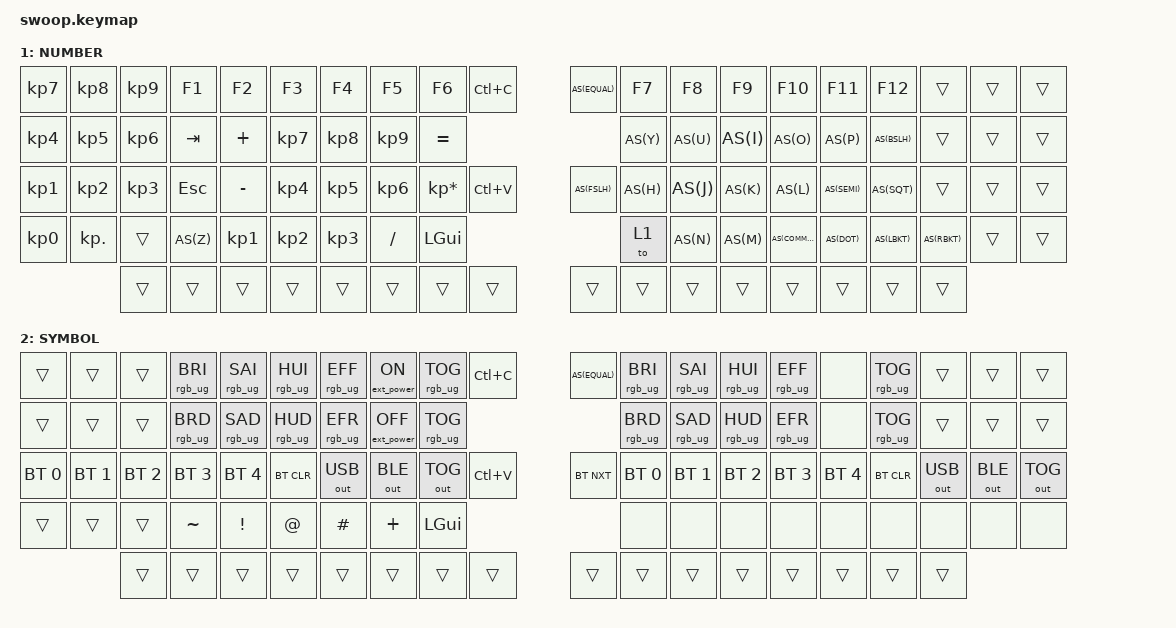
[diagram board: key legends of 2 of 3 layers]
#include <behaviors.dtsi>
#include <dt-bindings/zmk/keys.h>
#include <dt-bindings/zmk/rgb.h>
#include <dt-bindings/zmk/bt.h>
#include <dt-bindings/zmk/outputs.h>
#include <dt-bindings/zmk/ext_power.h>

#define DEFAULT 0
#define NUMBER  1
#define SYMBOL  2

#define AS(keycode) &as LS(keycode) keycode

/ {

       behaviors {
       as: auto_shift {
        compatible = "zmk,behavior-hold-tap";
        label = "AUTO_SHIFT";
        #binding-cells = <2>;
        tapping-term-ms = <160>;
        quick-tap-ms = <0>;
        flavor = "tap-preferred";
        bindings = <&kp>, <&kp>;
                };
modcp: mod_copy {
        compatible = "zmk,behavior-mod-morph";
        label = "MOD_COPY";
        #binding-cells = <0>;
        bindings = <&as LS(C) C>, <&kp C>;
        mods = <(MOD_LGUI | MOD_RGUI)>;
              };

        };


    macros {
        macro_phone: macro_phone {
            // 1351
            label = "MACRO_PHONE";
            compatible = "zmk,behavior-macro";
            #binding-cells = <0>;
            bindings
                = < &kp N1 &kp N3 &kp N5  &kp N1>
                ;
        };
        macro_email_q: macro_email_q {
            // 2894512440@qq.com
            label = "MACRO_EMAIL_QQ";
            compatible = "zmk,behavior-macro";
            #binding-cells = <0>;
            bindings 
                = < &kp N2 &kp N8 &kp N9 &kp N4 &kp N5 &kp  N1 &kp N2 &kp N4 &kp N4 &kp N0 
                    &kp AT &kp Q &kp Q &kp DOT  &kp C &kp O &kp M>
                ;
        };
        macro_email_g: macro_email_g {
            // 135115
            compatible = "zmk,behavior-macro";
            label = "MACRO_EMAIL_GMAIL";
            #binding-cells = <0>;
            bindings
                = < &kp N1 &kp N3 &kp N5  &kp N1 &kp N1 &kp N5 >
                ;
        };

    };


    keymap {
       compatible = "zmk,keymap";
        default_layer {
            label = "DEFAULT";
            bindings = <
  &kp KP_N7 &kp KP_N8 &kp KP_N9 &kp ESC &kp N1 &kp N2 &kp N3 &kp N4  &kp N5 &kp DEL       AS(EQUAL)AS(N6) AS(N7) AS(N8)  AS(N9) AS(N0) &kp MINUS &kp F10  &kp F11   &kp F12 
   &kp KP_N4 &kp KP_N5 &kp KP_N6 &kp TAB  &kp Q &kp W &kp E &kp R &kp T                                          AS(Y) AS(U) AS(I) AS(O) AS(P) AS(BSLH) &kp F7 &kp F8  &kp F9
   &kp KP_N1 &kp KP_N2 &kp KP_N3 &kp LSHFT  &kp A &kp S &kp D &kp F &kp G &kp ENTER                           AS(FSLH) AS(H)  AS(J) AS(K) AS(L) AS(SEMI) AS(SQT) &kp F4 &kp F5 &kp F6
   &kp KP_N0 &kp BSPC &kp LCTRL &kp Z &kp X &kp C &kp V &kp B &kp LALT                         &to 1 AS(N) AS(M) AS(COMMA) AS(DOT) AS(LBKT) AS(RBKT)  &kp F1 &kp F2 
    &kp DOWN &kp LGUI &kp LEFT &kp UP &kp RIGHT &kp SPACE &kp SPACE &kp SPACE                     &kp DEL &lt 2 LEFT &lt 1 RIGHT &kp C_VOL_UP  &kp C_VOL_DN  &kp C_BRI_UP
 
            >;
        };
            number_layer {
            label = "NUMBER";
            bindings = <
   &kp KP_N7 &kp KP_N8 &kp KP_N9   &kp F1 &kp F2 &kp F3 &kp F4 &kp F5  &kp F6 &kp LC(C)   AS(EQUAL) &kp F7 &kp F8 &kp F9 &kp F10     &kp F11   &kp F12  &trans &trans &trans  
     &kp KP_N4 &kp KP_N5 &kp KP_N6   &kp TAB  &kp PLUS &kp KP_N7 &kp KP_N8 &kp KP_N9  &kp EQUAL                      AS(Y) AS(U) AS(I) AS(O) AS(P) AS(BSLH)  &trans &trans &trans  
    &kp KP_N1 &kp KP_N2 &kp KP_N3   &kp ESC  &kp MINUS  &kp KP_N4 &kp KP_N5 &kp KP_N6  &kp KP_MULTIPLY &kp LC(V)       AS(FSLH) AS(H)  AS(J) AS(K) AS(L) AS(SEMI) AS(SQT)  &trans &trans &trans  
   &kp KP_N0 &kp KP_DOT          &trans   AS(Z) &kp KP_N1 &kp KP_N2 &kp KP_N3 &kp FSLH  &kp LGUI              &to 1 AS(N) AS(M) AS(COMMA) AS(DOT) AS(LBKT) AS(RBKT)   &trans &trans  
         &trans  &trans  &trans   &trans  &trans  &trans   &trans  &trans                       &trans  &trans  &trans   &trans  &trans  &trans   &trans  &trans  
            >;
        };
                     
        symbol_layer {
            label = "SYMBOL";
            bindings = <
   &trans  &trans  &trans  &rgb_ug RGB_BRI  &rgb_ug RGB_SAI  &rgb_ug RGB_HUI  &rgb_ug RGB_EFF   &ext_power EP_ON  &rgb_ug RGB_TOG  &kp LC(C)   AS(EQUAL) &rgb_ug RGB_BRI &rgb_ug RGB_SAI &rgb_ug RGB_HUI &rgb_ug RGB_EFF &none  &rgb_ug RGB_TOG  &trans &trans &trans
   &trans  &trans  &trans  &rgb_ug RGB_BRD  &rgb_ug RGB_SAD  &rgb_ug RGB_HUD  &rgb_ug RGB_EFR &ext_power EP_OFF        &rgb_ug RGB_TOG                  &rgb_ug RGB_BRD &rgb_ug RGB_SAD &rgb_ug RGB_HUD &rgb_ug RGB_EFR &none &rgb_ug RGB_TOG   &trans &trans &trans
  &bt BT_SEL 0 &bt BT_SEL 1 &bt BT_SEL 2 &bt BT_SEL 3 &bt BT_SEL 4 &bt BT_CLR &out OUT_USB  &out OUT_BLE  &out OUT_TOG   &kp LC(V)         &bt BT_NXT  &bt BT_SEL 0 &bt BT_SEL 1 &bt BT_SEL 2 &bt BT_SEL 3 &bt BT_SEL 4 &bt BT_CLR &out OUT_USB  &out OUT_BLE  &out OUT_TOG  
    &trans &trans        &trans  &kp TILDE &kp EXCL &kp AT &kp HASH  &kp PLUS  &kp LGUI              &none   &none   &none   &none   &none   &none           &none   &none &none 
          &trans  &trans  &trans   &trans  &trans  &trans   &trans  &trans                    &trans  &trans  &trans   &trans  &trans  &trans   &trans  &trans  
            >;
        };
         
   };
};
